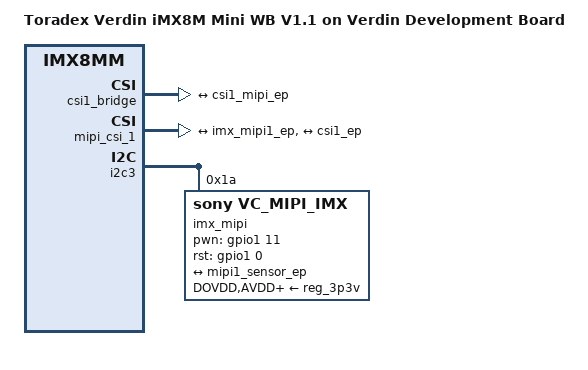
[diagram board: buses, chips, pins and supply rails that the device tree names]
// SPDX-License-Identifier: GPL-2.0+ OR MIT
/*
 * Copyright 2019 Toradex
 */

/dts-v1/;

#include "imx8mm-verdin-v1.1.dtsi"
#include "imx8mm-verdin-wifi.dtsi"
#include "imx8mm-verdin-dev.dtsi"

/ {
	model = "Toradex Verdin iMX8M Mini WB V1.1 on Verdin Development Board";
	compatible = "toradex,verdin-imx8mm-wifi-v1.1-dev",
		     "toradex,verdin-imx8mm-wifi-dev",
		     "toradex,verdin-imx8mm-wifi",
		     "toradex,verdin-imx8mm",
		     "fsl,imx8mm";
};

#define NUM_LANES  2

&csi1_bridge {
    fsl,mipi-mode;
    dma-coherent;
    status = "okay";

    port {
        csi1_ep: endpoint {
            remote-endpoint = <&csi1_mipi_ep>;
        };
    };
};

&mipi_csi_1 {
    mipi-phy-supply = <&reg_mipi_phy>;
    dma-coherent;
    status = "okay";

    port {
        #address-cells = <1>;
        #size-cells = <0>;

        mipi1_sensor_ep: endpoint@1 {
            csis-hs-settle = <13>;
            csis-clk-settle = <2>;
            csis-wclk;
            data-lanes = <NUM_LANES>;
            reg = <1>;
            remote-endpoint = <&imx_mipi1_ep>;
        };

        csi1_mipi_ep: endpoint@2 {
            reg = <2>;
            remote-endpoint = <&csi1_ep>;
        };
    };
};

&i2c3 {
    #address-cells = <1>;
    #size-cells = <0>;
    status = "okay";

    imx_mipi@1a {
        assigned-clocks = <&clk IMX8MM_CLK_CLKO1>;
        assigned-clock-parents = <&clk IMX8MM_CLK_24M>;
        assigned-clock-rates = <24000000>;   // original

        compatible = "sony,vc_mipi_imx";
        clock-names = "csi_mclk";
        clocks = <&clk IMX8MM_CLK_CLKO1>;
        DOVDD-supply = <&reg_3p3v>;
        AVDD-supply = <&reg_3p3v>;
        DVDD-supply = <&reg_3p3v>;
        PVDD-supply = <&reg_3p3v>;
        csi_id = <0>;
        mclk = <24000000>;
        mclk_source = <0>;
        pinctrl-names = "default";
        pinctrl-0 = <&pinctrl_gpio5>, <&pinctrl_gpio6>;
        pwn-gpios = <&gpio1 11 GPIO_ACTIVE_HIGH>;
        reg = <0x1a>;
        rst-gpios = <&gpio1 0 GPIO_ACTIVE_HIGH>;
        status = "okay";

        port {
            imx_mipi1_ep: endpoint {
                remote-endpoint = <&mipi1_sensor_ep>;
            };
        };
    };
};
